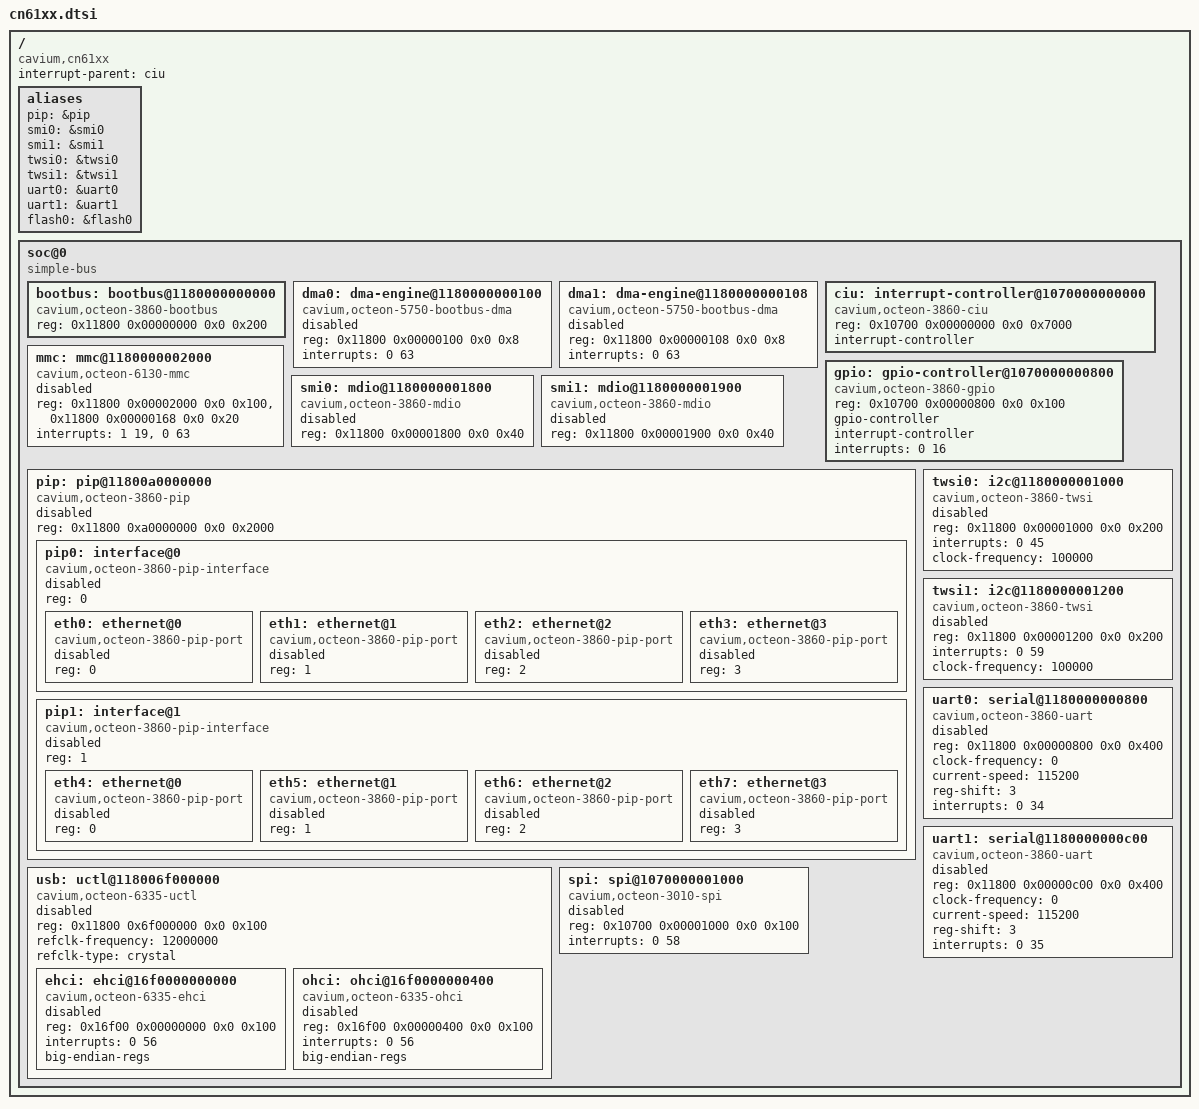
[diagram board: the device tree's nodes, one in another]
// SPDX-License-Identifier: GPL-2.0-or-later OR MIT
/dts-v1/;

/ {
	compatible = "cavium,cn61xx";
	#address-cells = <2>;
	#size-cells = <2>;
	interrupt-parent = <&ciu>;

	aliases {
		pip = &pip;
		smi0 = &smi0;
		smi1 = &smi1;
		twsi0 = &twsi0;
		twsi1 = &twsi1;
		uart0 = &uart0;
		uart1 = &uart1;
		flash0 = &flash0;
	};

	soc@0 {
		compatible = "simple-bus";
		#address-cells = <2>;
		#size-cells = <2>;
		ranges;

		bootbus: bootbus@1180000000000 {
			compatible = "cavium,octeon-3860-bootbus";
			#address-cells = <2>;
			#size-cells = <1>;
			reg = <0x11800 0x00000000 0x0 0x200>;
			ranges = <0x00 0  0       0x1f400000  0xc00000>,
				 <0x01 0  0x10000 0x30000000  0>,
				 <0x02 0  0       0x1d040000  0x10000>,
				 <0x03 0  0       0x1d050000  0x10000>,
				 <0x04 0  0       0x1d020000  0x10000>,
				 <0x05 0  0x10000 0x40000000  0>,
				 <0x06 0  0x10000 0x50000000  0>,
				 <0x07 0  0x10000 0x90000000  0>;
		};

		dma0: dma-engine@1180000000100 {
			status = "disabled";
			compatible = "cavium,octeon-5750-bootbus-dma";
			reg = <0x11800 0x00000100 0x0 0x8>;
			interrupts = <0 63>;
		};

		dma1: dma-engine@1180000000108 {
			status = "disabled";
			compatible = "cavium,octeon-5750-bootbus-dma";
			reg = <0x11800 0x00000108 0x0 0x8>;
			interrupts = <0 63>;
		};

		ciu: interrupt-controller@1070000000000 {
			compatible = "cavium,octeon-3860-ciu";
			reg = <0x10700 0x00000000 0x0 0x7000>;

			#interrupt-cells = <2>;
			interrupt-controller;
		};

		gpio: gpio-controller@1070000000800 {
			compatible = "cavium,octeon-3860-gpio";
			reg = <0x10700 0x00000800 0x0 0x100>;

			#gpio-cells = <2>;
			gpio-controller;

			#interrupt-cells = <2>;
			interrupt-controller;
			/* The GPIO pins connect to 16 consecutive CUI bits */
			interrupts = <0 16>; /* <0 17> <0 18> <0 19>
				     <0 20> <0 21> <0 22> <0 23>
				     <0 24> <0 25> <0 26> <0 27>
				     <0 28> <0 29> <0 30> <0 31>; */
		};

		mmc: mmc@1180000002000 {
			status = "disabled";
			compatible = "cavium,octeon-6130-mmc";
			#address-cells = <1>;
			#size-cells = <0>;
			reg = <0x11800 0x00002000 0x0 0x100>,
			      <0x11800 0x00000168 0x0 0x20>;

			interrupts = <1 19>, <0 63>;
		};

		smi0: mdio@1180000001800 {
			status = "disabled";
			compatible = "cavium,octeon-3860-mdio";
			#address-cells = <1>;
			#size-cells = <0>;
			reg = <0x11800 0x00001800 0x0 0x40>;
		};

		smi1: mdio@1180000001900 {
			status = "disabled";
			compatible = "cavium,octeon-3860-mdio";
			#address-cells = <1>;
			#size-cells = <0>;
			reg = <0x11800 0x00001900 0x0 0x40>;
		};

		pip: pip@11800a0000000 {
			status = "disabled";
			compatible = "cavium,octeon-3860-pip";
			#address-cells = <1>;
			#size-cells = <0>;
			reg = <0x11800 0xa0000000 0x0 0x2000>;

			pip0: interface@0 {
				status = "disabled";
				compatible = "cavium,octeon-3860-pip-interface";
				#address-cells = <1>;
				#size-cells = <0>;
				reg = <0>; /* Interface */

				eth0: ethernet@0 {
					status = "disabled";
					compatible = "cavium,octeon-3860-pip-port";
					reg = <0>; /* Port */
				};

				eth1: ethernet@1 {
					status = "disabled";
					compatible = "cavium,octeon-3860-pip-port";
					reg = <1>; /* Port */
				};

				eth2: ethernet@2 {
					status = "disabled";
					compatible = "cavium,octeon-3860-pip-port";
					reg = <2>; /* Port */
				};

				eth3: ethernet@3 {
					status = "disabled";
					compatible = "cavium,octeon-3860-pip-port";
					reg = <3>; /* Port */
				};
			};

			pip1: interface@1 {
				status = "disabled";
				compatible = "cavium,octeon-3860-pip-interface";
				#address-cells = <1>;
				#size-cells = <0>;
				reg = <1>; /* interface */

				eth4: ethernet@0 {
					status = "disabled";
					compatible = "cavium,octeon-3860-pip-port";
					reg = <0>; /* Port */
				};

				eth5: ethernet@1 {
					status = "disabled";
					compatible = "cavium,octeon-3860-pip-port";
					reg = <1>; /* Port */
				};

				eth6: ethernet@2 {
					status = "disabled";
					compatible = "cavium,octeon-3860-pip-port";
					reg = <2>; /* Port */
				};

				eth7: ethernet@3 {
					status = "disabled";
					compatible = "cavium,octeon-3860-pip-port";
					reg = <3>; /* Port */
				};
			};
		};

		twsi0: i2c@1180000001000 {
			status = "disabled";
			#address-cells = <1>;
			#size-cells = <0>;
			compatible = "cavium,octeon-3860-twsi";
			reg = <0x11800 0x00001000 0x0 0x200>;
			interrupts = <0 45>;
			clock-frequency = <100000>;
		};

		twsi1: i2c@1180000001200 {
			status = "disabled";
			#address-cells = <1>;
			#size-cells = <0>;
			compatible = "cavium,octeon-3860-twsi";
			reg = <0x11800 0x00001200 0x0 0x200>;
			interrupts = <0 59>;
			clock-frequency = <100000>;
		};

		usb: uctl@118006f000000 {
			status = "disabled";
			compatible = "cavium,octeon-6335-uctl";
			#address-cells = <2>;
			#size-cells = <2>;
			reg = <0x11800 0x6f000000 0x0 0x100>;
			ranges;

			refclk-frequency = <12000000>;
			refclk-type = "crystal";

			ehci: ehci@16f0000000000 {
				status = "disabled";
				compatible = "cavium,octeon-6335-ehci","usb-ehci";
				reg = <0x16f00 0x00000000 0x0 0x100>;
				interrupts = <0 56>;
				big-endian-regs;
			};

			ohci: ohci@16f0000000400 {
				status = "disabled";
				compatible = "cavium,octeon-6335-ohci","usb-ohci";
				reg = <0x16f00 0x00000400 0x0 0x100>;
				interrupts = <0 56>;
				big-endian-regs;
			};
		};

		uart0: serial@1180000000800 {
			status = "disabled";
			compatible = "cavium,octeon-3860-uart","ns16550";
			reg = <0x11800 0x00000800 0x0 0x400>;
			clock-frequency = <0>;
			current-speed = <115200>;
			reg-shift = <3>;
			interrupts = <0 34>;
		};

		uart1: serial@1180000000c00 {
			status = "disabled";
			compatible = "cavium,octeon-3860-uart","ns16550";
			reg = <0x11800 0x00000c00 0x0 0x400>;
			clock-frequency = <0>;
			current-speed = <115200>;
			reg-shift = <3>;
			interrupts = <0 35>;
		};

		spi: spi@1070000001000 {
			status = "disabled";
			compatible = "cavium,octeon-3010-spi";
			reg = <0x10700 0x00001000 0x0 0x100>;
			interrupts = <0 58>;
			#address-cells = <1>;
			#size-cells = <0>;
		};
	};
 };
